# ATxmega192A3U device description
Architecture: AVR8_XMEGA; Family: AVR XMEGA
Registers are 8-bit, access not given, no defined reset value unless marked. A register's access mark holds for its fields unless they carry their own. Offsets are from the block's base; [hi:lo] are bit positions; {n}, {i} and the like mark numbered series; 'fields as' and 'values as' point back to an identical list.

## NVM — Non-volatile Memory Controller
Instances: NVM 0x01C0
{0x0+i} ADDR{i} (i=0..2) — Address Register {i}
{0x4+i} DATA{i} (i=0..2) — Data Register {i}
0x0A CMD — Command
  [6:0] CMD
    0=NO_OPERATION (Noop/Ordinary LPM); 1=READ_USER_SIG_ROW (Read user signature row); 2=READ_CALIB_ROW (Read calibration row); 6=READ_EEPROM; 7=READ_FUSES (Read fuse byte); 8=WRITE_LOCK_BITS; 24=ERASE_USER_SIG_ROW (Erase user signature row); 26=WRITE_USER_SIG_ROW (Write user signature row); 32=ERASE_APP (Erase Application Section); 34=ERASE_APP_PAGE (Erase Application Section page); 35=LOAD_FLASH_BUFFER (Load Flash page buffer); 36=WRITE_APP_PAGE (Write Application Section page); 37=ERASE_WRITE_APP_PAGE (Erase-and-write Application Section page); 38=ERASE_FLASH_BUFFER (Erase/flush Flash page buffer); 42=ERASE_BOOT_PAGE (Erase Boot Section page); 43=ERASE_FLASH_PAGE; 44=WRITE_BOOT_PAGE (Write Boot Section page); 45=ERASE_WRITE_BOOT_PAGE (Erase-and-write Boot Section page); 46=WRITE_FLASH_PAGE; 47=ERASE_WRITE_FLASH_PAGE (Erase-and-write Flash Page); 48=ERASE_EEPROM; 50=ERASE_EEPROM_PAGE; 51=LOAD_EEPROM_BUFFER (Load EEPROM page buffer); 52=WRITE_EEPROM_PAGE; 53=ERASE_WRITE_EEPROM_PAGE (Erase-and-write EEPROM page); 54=ERASE_EEPROM_BUFFER (Erase/flush EEPROM page buffer); 56=APP_CRC (Application section CRC); 57=BOOT_CRC (Boot Section CRC); 58=FLASH_RANGE_CRC; 64=CHIP_ERASE (Erase Chip); 67=READ_NVM; 76=WRITE_FUSE (Write Fuse byte); 104=ERASE_BOOT (Erase Boot Section); 120=FLASH_CRC
0x0B CTRLA — Control Register A
  [0] CMDEX — Command Execute
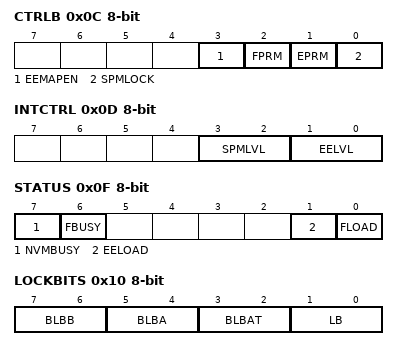
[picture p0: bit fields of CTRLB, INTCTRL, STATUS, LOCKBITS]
0x0C CTRLB — Control Register B
  [3] EEMAPEN — EEPROM Mapping Enable
  [2] FPRM — Flash Power Reduction Enable
  [1] EPRM — EEPROM Power Reduction Enable
  [0] SPMLOCK
0x0D INTCTRL — Interrupt Control
  [3:2] SPMLVL — SPM Interrupt Level
    0=OFF (Interrupt disabled); 1=LO (Low level); 2=MED (Medium level); 3=HI (High level)
  [1:0] EELVL — EEPROM Interrupt Level
    values as SPMLVL
0x0F STATUS
  [7] NVMBUSY — Non-volatile Memory Busy
  [6] FBUSY — Flash Memory Busy
  [1] EELOAD — EEPROM Page Buffer Active Loading
  [0] FLOAD — Flash Page Buffer Active Loading
0x10 LOCKBITS
  [7:6] BLBB — Boot Lock Bits - Boot Section
    0=RWLOCK (Read and write not allowed); 1=RLOCK (Read not allowed); 2=WLOCK (Write not allowed); 3=NOLOCK (No locks)
  [5:4] BLBA — Boot Lock Bits - Application Section
    values as BLBB
  [3:2] BLBAT — Boot Lock Bits - Application Table
    values as BLBB
  [1:0] LB — Lock Bits
    0=RWLOCK (Read and write not allowed); 2=WLOCK (Write not allowed); 3=NOLOCK (No locks)

## AC — Analog Comparator
Instances: ACA 0x0380, ACB 0x0390
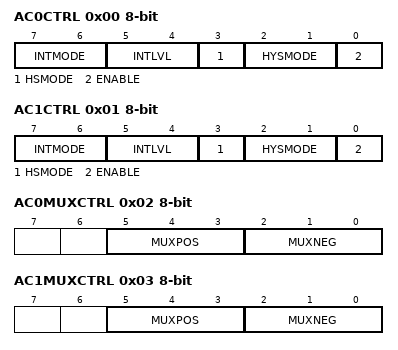
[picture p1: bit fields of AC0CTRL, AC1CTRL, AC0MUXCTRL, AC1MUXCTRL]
0x00 AC0CTRL — Analog Comparator 0 Control
  [7:6] INTMODE — Interrupt Mode
    0=BOTHEDGES (Interrupt on both edges); 2=FALLING (Interrupt on falling edge); 3=RISING (Interrupt on rising edge)
  [5:4] INTLVL — Interrupt Level
    0=OFF (Interrupt disabled); 1=LO (Low level); 2=MED (Medium level); 3=HI (High level)
  [3] HSMODE — High-speed Mode
  [2:1] HYSMODE — Hysteresis Mode
    0=NO (No hysteresis); 1=SMALL (Small hysteresis); 2=LARGE (Large hysteresis)
  [0] ENABLE
0x01 AC1CTRL — Analog Comparator 1 Control
  fields as AC0CTRL
0x02 AC0MUXCTRL — Analog Comparator 0 MUX Control
  [5:3] MUXPOS — MUX Positive Input
    {v}=PIN{v} (v=0..6); 7=DAC (DAC output)
  [2:0] MUXNEG — MUX Negative Input
    0=PIN0; 1=PIN1; 2=PIN3; 3=PIN5; 4=PIN7; 5=DAC (DAC output); 6=BANDGAP (Bandgap Reference); 7=SCALER (Internal voltage scaler)
0x03 AC1MUXCTRL — Analog Comparator 1 MUX Control
  fields as AC0MUXCTRL
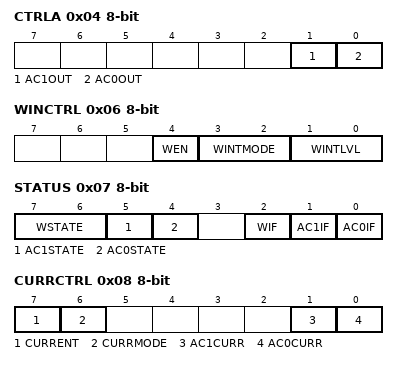
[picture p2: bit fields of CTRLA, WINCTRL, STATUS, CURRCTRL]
0x04 CTRLA — Control Register A
  [1] AC1OUT — Analog Comparator 1 Output Enable
  [0] AC0OUT — Analog Comparator 0 Output Enable
0x05 CTRLB — Control Register B
  [5:0] SCALEFAC — VCC Voltage Scaler Factor
0x06 WINCTRL — Window Mode Control
  [4] WEN — Window Mode Enable
  [3:2] WINTMODE — Window Interrupt Mode
    0=ABOVE (Interrupt on above window); 1=INSIDE (Interrupt on inside window); 2=BELOW (Interrupt on below window); 3=OUTSIDE (Interrupt on outside window)
  [1:0] WINTLVL — Window Interrupt Level
    0=OFF (Interrupt disabled); 1=LO (Low priority); 2=MED (Medium priority); 3=HI (High priority)
0x07 STATUS
  [7:6] WSTATE — Window Mode State
    0=ABOVE (Signal above window); 1=INSIDE (Signal inside window); 2=BELOW (Signal below window)
  [5] AC1STATE — Analog Comparator 1 State
  [4] AC0STATE — Analog Comparator 0 State
  [2] WIF — Window Mode Interrupt Flag
  [1] AC1IF — Analog Comparator 1 Interrupt Flag
  [0] AC0IF — Analog Comparator 0 Interrupt Flag
0x08 CURRCTRL — Current Source Control
  [7] CURRENT — Current Source Enable
  [6] CURRMODE — Current Mode
  [1] AC1CURR — AC1 Current Source Output Enable
  [0] AC0CURR — AC0 Current Source Output Enable
0x09 CURRCALIB — Current Source Calibration
  [3:0] CALIB
